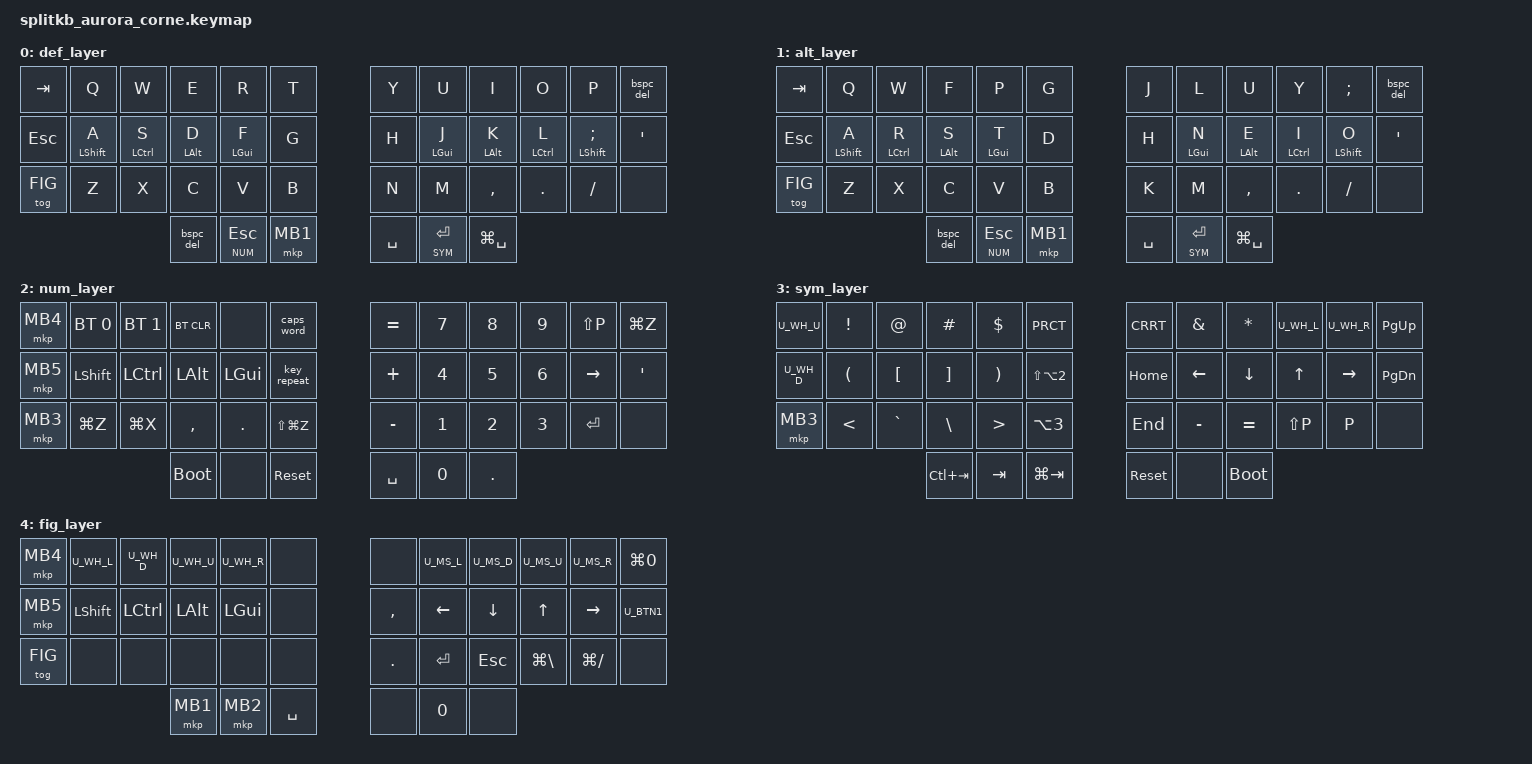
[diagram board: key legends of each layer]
#include <behaviors.dtsi>
#include <dt-bindings/zmk/keys.h>
#include <dt-bindings/zmk/bt.h>
#include <dt-bindings/zmk/mouse.h>

#include "../zmk-nodefree-config/keypos_def/keypos_42keys.h"
#include "../zmk-nodefree-config/helper.h"

#define DEF 0
#define ALT 1
#define NUM 2
#define SYM 3
#define FIG 4

#define U_RDO &kp LS(LG(Z))
#define U_PST &kp LG(V)
#define U_CPY &kp LG(C)
#define U_CUT &kp LG(X)
#define U_UND &kp LG(Z)

// #include "combos.dtsi"  // must be sourced after layer-shortcuts
#include "mouse.dtsi"

// Behavior Overrides
&lt {
    tapping-term-ms = <200>;
    flavor = "tap-preferred";
    tapping-term-ms = <200>;
    quick-tap-ms = <150>;
    global-quick-tap;
};

// Sticky key
&sk {
    // release-after-ms = <2000>;
    quick-release;
};

// Sticky layer
&sl {
    release-after-ms = <2000>;
};

// KEY POSITION REFERENCE
// ------------------------------------------------------------------------
// | 00 | 01 | 02 | 03 | 04 | 05 |          | 06 | 07 | 08 | 09 | 10 | 11 |
// | 12 | 13 | 14 | 15 | 16 | 17 |          | 18 | 19 | 20 | 21 | 22 | 23 |
// | 24 | 25 | 26 | 27 | 28 | 29 |          | 30 | 31 | 32 | 33 | 34 | 35 |
//                | 37 | 38 | 39 |          | 40 | 41 | 42 |


/ {
    macros {
        spotlight: spotlight {
            label = "spotlight";
            compatible = "zmk,behavior-macro";
            #binding-cells = <0>;
            bindings = <&macro_press &kp LGUI>, <&macro_tap &kp SPACE>, <&macro_release &kp LGUI>;
        };

        // Emoji
        mac_emoji: mac_emoji {
            label = "mac_emoji";
            compatible = "zmk,behavior-macro";
            #binding-cells = <0>;
            bindings = <&macro_press &kp LGUI>, <&macro_press &kp LCTRL>, <&macro_tap &kp SPACE>, <&macro_release &kp LCTRL>, <&macro_release &kp LGUI>;
        };

        ij: ij {
            label = "ij";
            compatible = "zmk,behavior-macro";
            //wait-ms = <30>;
            //tap-ms = <30>;
            #binding-cells = <0>;
            // ij (=LY in qwerty)
            //bindings = <&macro_tap &kp I &kp J>;
            bindings = <&macro_tap &kp L &kp Y>;
        };

        sch: sch {
            label = "sch";
            compatible = "zmk,behavior-macro";
            //wait-ms = <30>;
            //tap-ms = <30>;
            #binding-cells = <0>;
            // sch (=DCH in qwerty)
            //bindings = <&macro_tap &kp S &kp C &kp H>;
            bindings = <&macro_tap &kp D &kp C &kp H>;
        };

        // control + num
        cnum: cnum {
            label = "cnum";
            compatible = "zmk,behavior-macro";
            wait-ms = <0>;
            tap-ms = <30>;
            #binding-cells = <0>;
            bindings
                = <&macro_press &mo 1 &kp LCTRL>
                , <&macro_pause_for_release>
                , <&macro_release &mo 1 &kp LCTRL>;
        };

        // option + num
        anum: anum {
            label = "anum";
            compatible = "zmk,behavior-macro";
            wait-ms = <0>;
            tap-ms = <30>;
            #binding-cells = <0>;
            bindings
                = <&macro_press &mo 1 &kp LALT>
                , <&macro_pause_for_release>
                , <&macro_release &mo 1 &kp LALT>;
        };

        // gui + num
        gnum: gnum {
            label = "gnum";
            compatible = "zmk,behavior-macro";
            wait-ms = <0>;
            tap-ms = <30>;
            #binding-cells = <0>;
            bindings
                = <&macro_press &mo 1 &kp LGUI>
                , <&macro_pause_for_release>
                , <&macro_release &mo 1 &kp LGUI>;
        };

    };

#define CNUM &cnum
#define ANUM &anum
#define GNUM &gnum


    combos {
        compatible = "zmk,combos";

        combo_tab {
          timeout-ms = <20>;
          key-positions = <1 2>;
          bindings = <&kp TAB>;
        };

        COMBO_SCH {
          timeout-ms = <20>;
          key-positions = <3 4>;
          bindings = <&sch>;
        };

        combo_ij {
          timeout-ms = <20>;
          key-positions = <7 8>;
          bindings = <&ij>;
        };
        
        //  combo_enter {
        //    timeout-ms = <20>;
          //  key-positions = <13 14>;
          //  bindings = <&kp ENTER>;
        //};
    };

    behaviors {

        mo_sl: behavior_mo_sl {
            compatible = "zmk,behavior-hold-tap";
            label = "mo_sl";
            #binding-cells = <2>;
            flavor = "hold-preferred";
            tapping-term-ms = <200>;
            bindings = <&mo>, <&sl>;
        };

        bspc_del: backspace_delete {
            compatible = "zmk,behavior-mod-morph";
            label = "BACKSPACE_DELETE";
            #binding-cells = <0>;
            bindings = <&kp BACKSPACE>, <&kp DELETE>;
            mods = <(MOD_LCTL)>;
            // keep-mods = <(MOD_RSFT)>;
        };


        td_multi_mac: tap_dance_multi_mac {
            compatible = "zmk,behavior-tap-dance";
            label = "TAP_DANCE_MULTI_MAC";
            #binding-cells = <0>;
            tapping-term-ms = <200>;
            bindings = <&kp ESC>, <&spotlight>, <&mac_emoji>;
        };

        bm: bottom_row_mods {
            compatible = "zmk,behavior-hold-tap";
            label = "BOTTOM_ROW_MODS";
            #binding-cells = <2>;
            tapping-term-ms = <135>;
            quick-tap-ms = <0>;
            flavor = "tap-preferred";
            bindings = <&kp>, <&kp>;
        };

        cm: code_row_mods {
            compatible = "zmk,behavior-hold-tap";
            label = "CODE_ROW_MODS";
            #binding-cells = <2>;
            tapping-term-ms = <200>;
            quick-tap-ms = <0>;
            flavor = "tap-preferred";
            bindings = <&kp>, <&kp>;
            retro-tap;
        };

        sm: space_mod {
            compatible = "zmk,behavior-hold-tap";
            label = "SPACE_MOD";
            #binding-cells = <2>;
            flavor = "balanced";
            tapping-term-ms = <200>;
            quick-tap-ms = <125>;
            bindings = <&kp>, <&kp>;
        };

        gmt: global-quick-mod-tap {
            compatible = "zmk,behavior-hold-tap";
            label = "gmt";
            #binding-cells = <2>;
            flavor = "tap-preferred";
            tapping-term-ms = <220>;
            quick-tap-ms = <150>;
            global-quick-tap;
            bindings = <&kp>, <&kp>;
        };

        glt: global-quick-layer-tap {
            compatible = "zmk,behavior-hold-tap";
            label = "glt";
            #binding-cells = <2>;
            flavor = "tap-preferred";
            tapping-term-ms = <200>;
            quick-tap-ms = <150>;
            global-quick-tap;
            bindings = <&mo>, <&kp>;
        };

        gbt: global-quick-mousebutton-tap {
            compatible = "zmk,behavior-hold-tap";
            label = "gbt";
            #binding-cells = <2>;
            flavor = "tap-preferred";
            tapping-term-ms = <200>;
            quick-tap-ms = <150>;
            global-quick-tap;
            bindings = <&mkp>, <&kp>;
        };

        gmb: global-quick-modmousebutton-mousebutton {
            compatible = "zmk,behavior-hold-tap";
            label = "gmb";
            #binding-cells = <2>;
            flavor = "tap-preferred";
            tapping-term-ms = <200>;
            quick-tap-ms = <150>;
            global-quick-tap;
            bindings = <&mkp>, <&mkp>;
        };

        gkm: global-mod-mouse-tap {
            compatible = "zmk,behavior-hold-tap";
            label = "gkm";
            #binding-cells = <2>;
            flavor = "tap-preferred";
            tapping-term-ms = <200>;
            quick-tap-ms = <150>;
            global-quick-tap;
            bindings = <&kp>, <&mkp>;
        };


};

// KEY POSITION REFERENCE
// ------------------------------------------------------------------------
// | 00 | 01 | 02 | 03 | 04 | 05 |          | 06 | 07 | 08 | 09 | 10 | 11 |
// | 12 | 13 | 14 | 15 | 16 | 17 |          | 18 | 19 | 20 | 21 | 22 | 23 |
// | 24 | 25 | 26 | 27 | 28 | 29 |          | 30 | 31 | 32 | 33 | 34 | 35 |
//                | 37 | 38 | 39 |          | 40 | 41 | 42 |

// to fix: &gmb LG(MB3) MB3


    keymap {
        compatible = "zmk,keymap";

        // to properly map Colemak to Qwerty on macOS, we use P for semicolon

        def_layer {
          // ---------------------------------------------------------------------------------------
          // |  TAB |  Q  |  W  |  E  |  R  |  T  |           |  Y  |  U  |  I  |  O  |  P  | BKSP |
          // | CTRL |  A  |  S  |  D  |  F  |  G  |           |  H  |  J  |  K  |  L  |  ;  |  '   |
          // | SHFT |  Z  |  X  |  C  |  V  |  B  |           |  N  |  M  |  ,  |  .  |  /  |      |
          //                    | GUI |  L1 | SPC |           | ENT |  L2 | ALT |
             bindings = <
                &kp TAB     &kp Q          &kp W           &kp E           &kp R           &kp T                  &kp Y         &kp U          &kp I           &kp O          &kp P             &bspc_del
                &kp ESC     &gmt LSHFT A   &gmt LCTRL S    &gmt LALT D     &gmt LGUI F     &kp G                  &kp H         &gmt LGUI J    &gmt LALT K     &gmt LCTRL L   &gmt LSHFT SEMI   &kp SQT
                &tog FIG    &kp Z          &kp X           &kp C           &kp V           &kp B                  &kp N         &kp M          &kp COMMA       &kp DOT        &kp SLASH         &none
                                                           &bspc_del       &glt NUM ESC    &mkp MB1               &kp SPACE     &glt SYM RET   &kp LG(SPACE)
            >;
        };

        alt_layer {
           // ---------------------------------------------------------------------------------------
           // |  TAB |  Q  |  W  |  F  |  P  |  G  |           |  J  |  L  |  U  |  Y  |  '  | BKSP |
           // | CTRL |  A  |  R  |  S  |  T  |  D  |           |  H  |  N  |  E  |  I  |  O  |  '   |
           // | SHFT |  Z  |  X  |  C  |  V  |  B  |           |  K  |  M  |  ,  |  .  |  /  |      |
           //                    | GUI |  L1 | SPC |           | ENT |  L2 | ALT |n
             bindings = <
                 &kp TAB     &kp Q          &kp W          &kp F           &kp P           &kp G                  &kp J         &kp L          &kp U           &kp Y          &kp SEMI          &bspc_del
                 &kp ESC     &gmt LSHFT A   &gmt LCTRL R   &gmt LALT S     &gmt LGUI T     &kp D                  &kp H         &gmt LGUI N    &gmt LALT E     &gmt LCTRL I   &gmt LSHFT O      &kp SQT
                 &tog FIG    &kp Z          &kp X          &kp C           &kp V           &kp B                  &kp K         &kp M          &kp COMMA       &kp DOT        &kp SLASH         &none
                                                           &bspc_del       &glt NUM ESC    &mkp MB1               &kp SPACE     &glt SYM RET   &kp LG(SPACE)
             >;
      };

        num_layer {
            bindings = <
                &mkp MB4    &bt BT_SEL 0   &bt BT_SEL 1    &bt BT_CLR      &none           &caps_word             &kp EQL       &kp NUM_7      &kp NUM_8       &kp NUM_9      &kp LS(P)         U_UND
                &mkp MB5    &kp LSHFT      &kp LCTRL       &kp LALT        &kp LGUI        &key_repeat            &kp PLUS      &kp NUM_4      &kp NUM_5       &kp NUM_6      &kp RIGHT         &kp SQT
                &mkp MB3    U_UND          U_CUT           &kp COMMA       &kp DOT         U_RDO                  &kp MINUS     &kp NUM_1      &kp NUM_2       &kp NUM_3      &kp RET           &none
                                                           &bootloader     &none           &sys_reset             &kp SPACE     &kp NUM_0      &kp DOT
            >;
        };

        sym_layer {
            bindings = <
                U_WH_U      &kp EXCL       &kp AT          &kp HASH        &kp DLLR        &kp PRCT               &kp CRRT      &kp AMPS        &kp ASTRK      U_WH_L         U_WH_R             &kp PG_UP
                U_WH_D      &kp LPAR       &kp LBKT        &kp RBKT        &kp RPAR        &kp LS(LA(NUM_2))      &kp HOME      &kp LEFT        &kp DOWN       &kp UP         &kp RIGHT          &kp PG_DN
                &mkp MB3    &kp LT         &kp GRAVE       &kp BSLH        &kp GT          &kp LA(NUM_3)          &kp END       &kp MINUS       &kp EQL        &kp LS(P)      &kp P              &none
                                                           &kp LC(TAB)     &kp TAB         &kp LG(TAB)            &sys_reset    &none           &bootloader
            >;
        };
                                          
        fig_layer {
            bindings = <
                &mkp MB4    U_WH_L         U_WH_D          U_WH_U          U_WH_R          &none                  &none         U_MS_L          U_MS_D         U_MS_U        U_MS_R            &kp LG(NUM_0)
                &mkp MB5    &kp LSHFT      &kp LCTRL       &kp LALT        &kp LGUI        &none                  &kp COMMA     &kp LEFT        &kp DOWN       &kp UP        &kp RIGHT         U_BTN1
                &tog FIG    &none          &none           &none           &none           &none                  &kp DOT       &kp RET         &kp ESC        &kp LG(BSLH)  &kp LG(SLASH)     &none
                                                           &mkp MB1        &mkp MB2        &kp SPACE              &none         &kp NUM_0       &none
            >;
        };

    };
};
